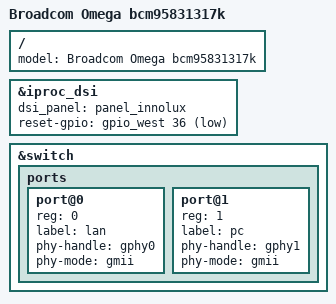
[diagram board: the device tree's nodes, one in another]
// SPDX-License-Identifier: (GPL-2.0 or BSD-3-Clause)
/*
 *  Copyright(c) 2019 Broadcom
 */

/dts-v1/;

#include "arm/innolux-lcd-panel.dtsi"
#include "omega-base-board.dtsi"
#include "bcm58313.dtsi"
#include "bcm95831x-svk-common.dtsi"

#include <dt-bindings/gpio/gpio.h>

/ {
	model = "Broadcom Omega bcm95831317k";
};

&iproc_dsi {
	dsi_panel = <&panel_innolux>;
	reset-gpio = <&gpio_west 36 GPIO_ACTIVE_LOW>;
	status = "okay";
};

&switch {
	status = "okay";
	ports {
		#address-cells = <1>;
		#size-cells = <0>;
		port@0 {
			reg = <0>;
			label = "lan";
			phy-handle = <&gphy0>;
			phy-mode = "gmii";
		};
		port@1 {
			reg = <1>;
			label = "pc";
			phy-handle = <&gphy1>;
			phy-mode = "gmii";
		};
	};
};
